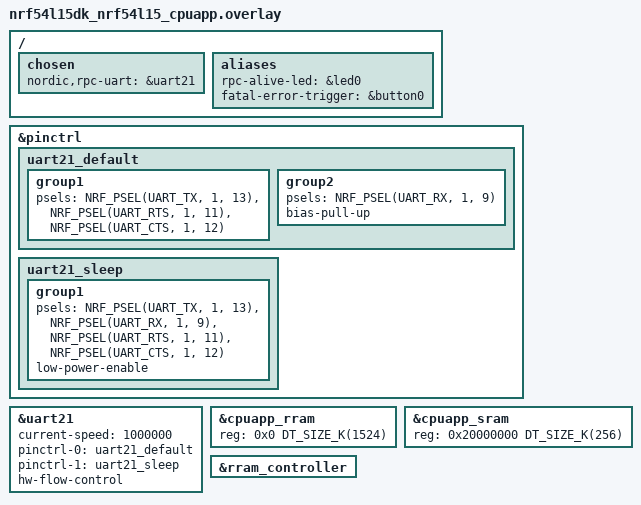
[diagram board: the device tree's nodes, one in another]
/* Copyright (c) 2024 Nordic Semiconductor ASA
 *
 * SPDX-License-Identifier: LicenseRef-Nordic-5-Clause
 */

/ {
	chosen {
		nordic,rpc-uart = &uart21;
	};

	aliases {
		rpc-alive-led = &led0;
		fatal-error-trigger = &button0;

		/* delete all buttons except button0 to free GPIO pins assigned to uart21 below */
		/delete-property/ sw1;
		/delete-property/ sw2;
		/delete-property/ sw3;
	};
};

/delete-node/ &button1;
/delete-node/ &button2;
/delete-node/ &button3;

&pinctrl {
	uart21_default: uart21_default {
		group1 {
			psels = <NRF_PSEL(UART_TX, 1, 13)>,
			        <NRF_PSEL(UART_RTS, 1, 11)>,
			        <NRF_PSEL(UART_CTS, 1, 12)>;
		};
		group2 {

			psels = <NRF_PSEL(UART_RX, 1, 9)>;
			bias-pull-up;
		};
	};

	uart21_sleep: uart21_sleep {
		group1 {
			psels = <NRF_PSEL(UART_TX, 1, 13)>,
			        <NRF_PSEL(UART_RX, 1, 9)>,
			        <NRF_PSEL(UART_RTS, 1, 11)>,
			        <NRF_PSEL(UART_CTS, 1, 12)>;
			low-power-enable;
		};
	};
};

&uart21 {
	status = "okay";
	current-speed = <1000000>;
	pinctrl-0 = <&uart21_default>;
	pinctrl-1 = <&uart21_sleep>;
	pinctrl-names = "default", "sleep";
	hw-flow-control;
};

/* restore full RRAM and SRAM space - by default some parts are dedicated to FLRP */
&cpuapp_rram {
	reg = <0x0 DT_SIZE_K(1524)>;
};

&cpuapp_sram {
	reg = <0x20000000 DT_SIZE_K(256)>;
	ranges = <0x0 0x20000000  0x40000>;
};

&rram_controller {
	/delete-node/ cpuflpr_sram;
	/delete-node/ cpuflpr_rram;
};
